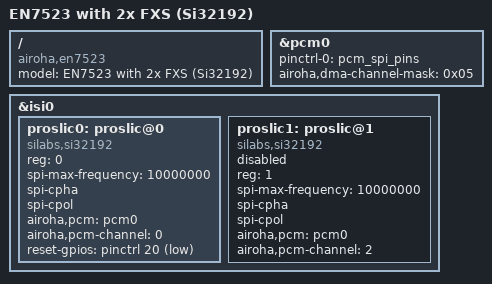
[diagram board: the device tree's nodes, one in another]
// SPDX-License-Identifier: GPL-2.0
/*
 * Example: EN7523 board with two FXS ports on a Skyworks Si32192.
 *
 * Modelled on the TP-Link XX230v. The visible difference from the
 * EN7528 example is not the SLIC at all -- it is the PCM block:
 * gen2 descriptors and 32 timeslots, selected by the compatible in
 * en7523-voice.dtsi, and the confirmed PCM interrupt (GIC_SPI 27), so
 * the driver runs interrupt-driven instead of
 * polled.
 */

/dts-v1/;

#include <dt-bindings/gpio/gpio.h>
#include <dt-bindings/interrupt-controller/arm-gic.h>

#include "en7523.dtsi"
#include "en7523-voice.dtsi"

/ {
	model = "EN7523 with 2x FXS (Si32192)";
	compatible = "airoha,en7523";
};

&pcm0 {
	/*
	 * ISI multiplexes the SLIC control channel onto the PCM pins
	 * themselves (see isi0 below), so this is pcm_spi_pins, not
	 * pcm1_pins -- the same pin group zsi0 would need if this board
	 * used a ZSI part instead.
	 */
	pinctrl-names = "default";
	pinctrl-0 = <&pcm_spi_pins>;
	airoha,dma-channel-mask = <0x05>;
	status = "okay";
};

&isi0 {
	status = "okay";

	/*
	 * The wrapper's own channel-select register picks the device, not
	 * a real chip-select pin -- reg is 0 and 1 here, not offset by a
	 * shared flash chip select the way a real SPI bus would be.
	 */
	proslic0: proslic@0 {
		compatible = "silabs,si32192";
		reg = <0>;
		spi-max-frequency = <10000000>;
		spi-cpha;
		spi-cpol;

		airoha,pcm = <&pcm0>;
		airoha,pcm-channel = <0>;

		reset-gpios = <&pinctrl 20 GPIO_ACTIVE_LOW>;

		status = "okay";
	};

	proslic1: proslic@1 {
		compatible = "silabs,si32192";
		reg = <1>;
		spi-max-frequency = <10000000>;
		spi-cpha;
		spi-cpol;

		airoha,pcm = <&pcm0>;
		airoha,pcm-channel = <2>;

		/*
		 * A second physical device on the same ISI bus needs the
		 * chip-SCU DEV2 bits too -- see en75xx_isi_spi.c's file
		 * header. Untested with two devices present; leave disabled
		 * until that is verified on real hardware.
		 */
		status = "disabled";
	};
};
